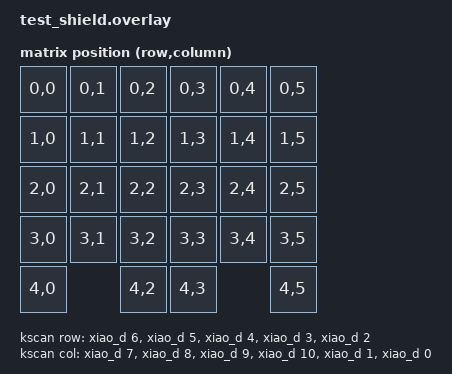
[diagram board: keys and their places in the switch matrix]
// This file was generated from a template. Edit it to match your keyboard.
// See https://zmk.dev/docs/development/hardware-integration/new-shield for more
// instructions.

#include <dt-bindings/zmk/matrix_transform.h>

#include "test_shield-layouts.dtsi"

/ {
    chosen {
        zmk,physical-layout = &default_layout;
    };

    kscan: kscan {
        // If the hardware does not use a switch matrix, change this to the
        // appropriate driver and update the properties below to match.
        // See https://zmk.dev/docs/config/kscan for supported key scan drivers.
        compatible = "zmk,kscan-gpio-matrix";
        // Set this to "col2row" or "row2col" to match the hardware. If using
        // "row2col", change the col-gpios to (GPIO_ACTIVE_HIGH | GPIO_PULL_DOWN)
        // and the row-gpios to GPIO_ACTIVE_HIGH.
        diode-direction = "row2col";
        wakeup-source;

        // Replace these comments with the GPIO pins in the matrix.
        // See https://zmk.dev/docs/development/hardware-integration/new-shield#shield-overlays
        col-gpios
            = <&xiao_d 7 (GPIO_ACTIVE_HIGH | GPIO_PULL_DOWN)>
            , <&xiao_d 8 (GPIO_ACTIVE_HIGH | GPIO_PULL_DOWN)>
            , <&xiao_d 9 (GPIO_ACTIVE_HIGH | GPIO_PULL_DOWN)>
            , <&xiao_d 10 (GPIO_ACTIVE_HIGH | GPIO_PULL_DOWN)>
            , <&xiao_d 1 (GPIO_ACTIVE_HIGH | GPIO_PULL_DOWN)>
            , <&xiao_d 0 (GPIO_ACTIVE_HIGH | GPIO_PULL_DOWN)>
            ;

        row-gpios
            = <&xiao_d 6 GPIO_ACTIVE_HIGH>
            , <&xiao_d 5 GPIO_ACTIVE_HIGH>
            , <&xiao_d 4 GPIO_ACTIVE_HIGH>
            , <&xiao_d 3 GPIO_ACTIVE_HIGH>
            , <&xiao_d 2 GPIO_ACTIVE_HIGH>
            ;
    };

    default_transform: default_transform {
        // See https://zmk.dev/docs/development/hardware-integration/new-shield#matrix-transform
        // for how to configure this
        compatible = "zmk,matrix-transform";
        columns = <6>;
        rows = <5>;

        map = <
            RC(0, 0) RC(0, 1) RC(0, 2) RC(0, 3) RC(0, 4) RC(0, 5)
            RC(1, 0) RC(1, 1) RC(1, 2) RC(1, 3) RC(1, 4) RC(1, 5)
            RC(2, 0) RC(2, 1) RC(2, 2) RC(2, 3) RC(2, 4) RC(2, 5)
            RC(3, 0) RC(3, 1) RC(3, 2) RC(3, 3) RC(3, 4) RC(3, 5)
            RC(4, 0)          RC(4, 2) RC(4, 3)          RC(4, 5)
        >;
    };
};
